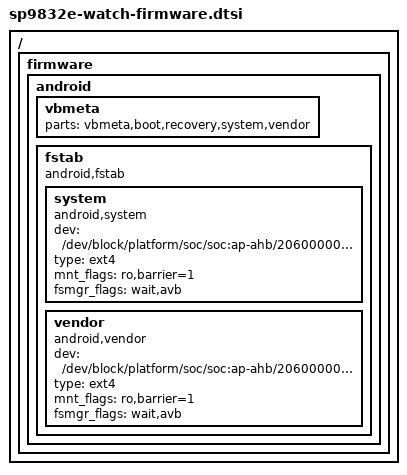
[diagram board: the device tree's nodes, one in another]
// SPDX-License-Identifier: GPL-2.0
/*
 * Android firmware node of the watches, as in their stock DTs (identical on
 * the K18, DM63, DW100U, MT107, MT108 and DM82). The stock 8.1 init mounts
 * /system and /vendor early from this fstab; the ramdisk fstab has neither,
 * so without it the stock system does not come up.
 *
 * Replaces the vbmeta parts and adds the fstab over sp9832e-mach.dtsi, whose
 * node comes from a later SPRD platform (ramdisk fstab, no system/vendor).
 */

/ {
	firmware {
		android {
			vbmeta {
				parts = "vbmeta,boot,recovery,system,vendor";
			};

			fstab {
				compatible = "android,fstab";

				system {
					compatible = "android,system";
					dev = "/dev/block/platform/soc/soc:ap-ahb/20600000.sdio/by-name/system";
					type = "ext4";
					mnt_flags = "ro,barrier=1";
					fsmgr_flags = "wait,avb";
				};

				vendor {
					compatible = "android,vendor";
					dev = "/dev/block/platform/soc/soc:ap-ahb/20600000.sdio/by-name/vendor";
					type = "ext4";
					mnt_flags = "ro,barrier=1";
					fsmgr_flags = "wait,avb";
				};
			};
		};
	};
};
